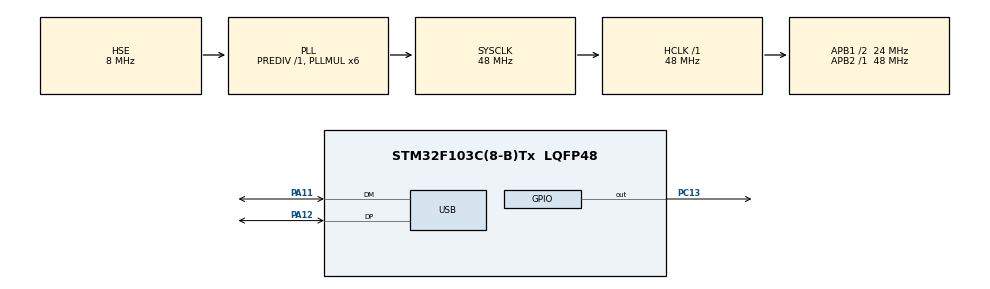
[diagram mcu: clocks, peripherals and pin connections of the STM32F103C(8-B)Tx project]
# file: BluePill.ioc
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Mcu.Family=STM32F1
Mcu.Name=STM32F103C(8-B)Tx
Mcu.Package=LQFP48
NVIC.PriorityGroup=NVIC_PRIORITYGROUP_4
NVIC.TIM1_UP_IRQn=true\:3\:0\:true\:false\:true\:true\:true
NVIC.TIM2_IRQn=true\:4\:0\:true\:false\:true\:true\:true
NVIC.USB_HP_CAN1_TX_IRQn=true\:1\:0\:true\:false\:true\:true\:true
NVIC.USB_LP_CAN1_RX0_IRQn=true\:2\:0\:true\:false\:true\:true\:true
PA11.Mode=Device
PA11.Signal=USB_DM
PA12.Mode=Device
PA12.Signal=USB_DP
PC13-TAMPER-RTC.Signal=GPIO_Output
PD0-OSC_IN.Mode=HSE-External-Oscillator
PD0-OSC_IN.Signal=RCC_OSC_IN
PD1-OSC_OUT.Mode=HSE-External-Oscillator
PD1-OSC_OUT.Signal=RCC_OSC_OUT
ProjectManager.HeapSize=0x200
ProjectManager.StackSize=0x400
ProjectManager.TargetToolchain=STM32CubeIDE
RCC.AHBFreq_Value=48000000
RCC.APB1CLKDivider=RCC_HCLK_DIV2
RCC.APB1Freq_Value=24000000
RCC.APB1TimFreq_Value=48000000
RCC.APB2Freq_Value=48000000
RCC.APB2TimFreq_Value=48000000
RCC.HCLKFreq_Value=48000000
RCC.PLLMUL=RCC_PLL_MUL6
RCC.PLLSourceVirtual=RCC_PLLSOURCE_HSE
RCC.SYSCLKFreq_VALUE=48000000
RCC.SYSCLKSource=RCC_SYSCLKSOURCE_PLLCLK
RCC.USBFreq_Value=48000000
TIM1.AutoReloadPreload=TIM_AUTORELOAD_PRELOAD_ENABLE
TIM1.Period=60000
TIM1.Prescaler=48000
TIM1.RepetitionCounter=4
TIM2.AutoReloadPreload=TIM_AUTORELOAD_PRELOAD_ENABLE
TIM2.Period=1000
TIM2.Prescaler=48000
USB_DEVICE.CLASS_NAME_FS=HID
USB_DEVICE.PID_HID_FS=22352
USB_DEVICE.VID=1155
USB_DEVICE.VirtualMode=Hid
USB_DEVICE.VirtualModeFS=Hid_FS
VP_SYS_VS_ND.Mode=No_Debug
VP_TIM1_VS_ClockSourceINT.Mode=Internal
VP_TIM2_VS_ClockSourceINT.Mode=Internal
VP_USB_DEVICE_VS_USB_DEVICE_HID_FS.Mode=HID_FS
board=custom

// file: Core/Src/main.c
/* USER CODE BEGIN Header */
/**
  ******************************************************************************
  * @file           : main.c
  * @brief          : Main program body
  ******************************************************************************
  * @attention
  *
  * <h2><center>&copy; Copyright (c) 2020 STMicroelectronics.
  * All rights reserved.</center></h2>
  *
  * This software component is licensed by ST under BSD 3-Clause license,
  * the "License"; You may not use this file except in compliance with the
  * License. You may obtain a copy of the License at:
  *                        opensource.org/licenses/BSD-3-Clause
  *
  ******************************************************************************
  */
/* USER CODE END Header */

#include "main.h"
#include "usb_device.h"

/* USER CODE BEGIN Includes */
#include "usbd_hid.h"
/* USER CODE END Includes */

/* USER CODE BEGIN PD */
#define MBUFSIZ 5
/* USER CODE END PD */

TIM_HandleTypeDef htim1;
TIM_HandleTypeDef htim2;

/* USER CODE BEGIN PV */
static __IO uint8_t TIM1Cplt;
static __IO uint8_t TIM2Cplt;
static int8_t mbuf[MBUFSIZ];
/* USER CODE END PV */

void SystemClock_Config(void);
static void MX_GPIO_Init(void);
static void MX_TIM1_Init(void);
static void MX_TIM2_Init(void);
/* USER CODE BEGIN PFP */
static void Mouse_SendData(void);
/* USER CODE END PFP */

/* USER CODE BEGIN 0 */
extern USBD_HandleTypeDef hUsbDeviceFS;
/* USER CODE END 0 */

int main(void)
{

  /* MCU Configuration--------------------------------------------------------*/

  /* Reset of all peripherals, Initializes the Flash interface and the Systick. */
  HAL_Init();

  /* Configure the system clock */
  SystemClock_Config();

  /* Initialize all configured peripherals */
  MX_GPIO_Init();
  MX_TIM1_Init();
  MX_TIM2_Init();
  MX_USB_DEVICE_Init();
  /* USER CODE BEGIN 2 */
  // Update ARR for TIM1
  htim1.Instance->EGR |= TIM_EGR_UG;
  __HAL_TIM_CLEAR_IT(&htim1, TIM_IT_UPDATE);
  // Update ARR for TIM2
  htim2.Instance->EGR |= TIM_EGR_UG;
  __HAL_TIM_CLEAR_IT(&htim2, TIM_IT_UPDATE);
  // Start TIM1
  TIM1Cplt = 0;
  HAL_TIM_Base_Start_IT(&htim1);
  /* USER CODE END 2 */

  /* Infinite loop */
  while (1)
  {

    /* USER CODE BEGIN 3 */
	  Mouse_SendData();
  }
  /* USER CODE END 3 */
}

void SystemClock_Config(void)
{
  RCC_OscInitTypeDef RCC_OscInitStruct = {0};
  RCC_ClkInitTypeDef RCC_ClkInitStruct = {0};
  RCC_PeriphCLKInitTypeDef PeriphClkInit = {0};

  /** Initializes the CPU, AHB and APB busses clocks
  */
  RCC_OscInitStruct.OscillatorType = RCC_OSCILLATORTYPE_HSE;
  RCC_OscInitStruct.HSEState = RCC_HSE_ON;
  RCC_OscInitStruct.HSEPredivValue = RCC_HSE_PREDIV_DIV1;
  RCC_OscInitStruct.HSIState = RCC_HSI_ON;
  RCC_OscInitStruct.PLL.PLLState = RCC_PLL_ON;
  RCC_OscInitStruct.PLL.PLLSource = RCC_PLLSOURCE_HSE;
  RCC_OscInitStruct.PLL.PLLMUL = RCC_PLL_MUL6;
  if (HAL_RCC_OscConfig(&RCC_OscInitStruct) != HAL_OK)
  {
    Error_Handler();
  }
  /** Initializes the CPU, AHB and APB busses clocks
  */
  RCC_ClkInitStruct.ClockType = RCC_CLOCKTYPE_HCLK|RCC_CLOCKTYPE_SYSCLK
                              |RCC_CLOCKTYPE_PCLK1|RCC_CLOCKTYPE_PCLK2;
  RCC_ClkInitStruct.SYSCLKSource = RCC_SYSCLKSOURCE_PLLCLK;
  RCC_ClkInitStruct.AHBCLKDivider = RCC_SYSCLK_DIV1;
  RCC_ClkInitStruct.APB1CLKDivider = RCC_HCLK_DIV2;
  RCC_ClkInitStruct.APB2CLKDivider = RCC_HCLK_DIV1;

  if (HAL_RCC_ClockConfig(&RCC_ClkInitStruct, FLASH_LATENCY_1) != HAL_OK)
  {
    Error_Handler();
  }
  PeriphClkInit.PeriphClockSelection = RCC_PERIPHCLK_USB;
  PeriphClkInit.UsbClockSelection = RCC_USBCLKSOURCE_PLL;
  if (HAL_RCCEx_PeriphCLKConfig(&PeriphClkInit) != HAL_OK)
  {
    Error_Handler();
  }
}

static void MX_TIM1_Init(void)
{

  TIM_ClockConfigTypeDef sClockSourceConfig = {0};
  TIM_MasterConfigTypeDef sMasterConfig = {0};

  htim1.Instance = TIM1;
  htim1.Init.Prescaler = 48000;
  htim1.Init.CounterMode = TIM_COUNTERMODE_UP;
  htim1.Init.Period = 60000;
  //htim1.Init.Period = 2000;
  htim1.Init.ClockDivision = TIM_CLOCKDIVISION_DIV1;
  htim1.Init.RepetitionCounter = 4;
  htim1.Init.AutoReloadPreload = TIM_AUTORELOAD_PRELOAD_ENABLE;
  if (HAL_TIM_Base_Init(&htim1) != HAL_OK)
  {
    Error_Handler();
  }
  sClockSourceConfig.ClockSource = TIM_CLOCKSOURCE_INTERNAL;
  if (HAL_TIM_ConfigClockSource(&htim1, &sClockSourceConfig) != HAL_OK)
  {
    Error_Handler();
  }
  sMasterConfig.MasterOutputTrigger = TIM_TRGO_RESET;
  sMasterConfig.MasterSlaveMode = TIM_MASTERSLAVEMODE_DISABLE;
  if (HAL_TIMEx_MasterConfigSynchronization(&htim1, &sMasterConfig) != HAL_OK)
  {
    Error_Handler();
  }

}

static void MX_TIM2_Init(void)
{

  TIM_ClockConfigTypeDef sClockSourceConfig = {0};
  TIM_MasterConfigTypeDef sMasterConfig = {0};

  htim2.Instance = TIM2;
  htim2.Init.Prescaler = 48000;
  htim2.Init.CounterMode = TIM_COUNTERMODE_UP;
  htim2.Init.Period = 1000;
  htim2.Init.ClockDivision = TIM_CLOCKDIVISION_DIV1;
  htim2.Init.AutoReloadPreload = TIM_AUTORELOAD_PRELOAD_ENABLE;
  if (HAL_TIM_Base_Init(&htim2) != HAL_OK)
  {
    Error_Handler();
  }
  sClockSourceConfig.ClockSource = TIM_CLOCKSOURCE_INTERNAL;
  if (HAL_TIM_ConfigClockSource(&htim2, &sClockSourceConfig) != HAL_OK)
  {
    Error_Handler();
  }
  sMasterConfig.MasterOutputTrigger = TIM_TRGO_RESET;
  sMasterConfig.MasterSlaveMode = TIM_MASTERSLAVEMODE_DISABLE;
  if (HAL_TIMEx_MasterConfigSynchronization(&htim2, &sMasterConfig) != HAL_OK)
  {
    Error_Handler();
  }

}

static void MX_GPIO_Init(void)
{
  GPIO_InitTypeDef GPIO_InitStruct = {0};

  /* GPIO Ports Clock Enable */
  __HAL_RCC_GPIOC_CLK_ENABLE();
  __HAL_RCC_GPIOD_CLK_ENABLE();
  __HAL_RCC_GPIOA_CLK_ENABLE();

  /*Configure GPIO pin Output Level */
  HAL_GPIO_WritePin(GPIOC, GPIO_PIN_13, GPIO_PIN_RESET);

  /*Configure GPIO pin : PC13 */
  GPIO_InitStruct.Pin = GPIO_PIN_13;
  GPIO_InitStruct.Mode = GPIO_MODE_OUTPUT_PP;
  GPIO_InitStruct.Pull = GPIO_NOPULL;
  GPIO_InitStruct.Speed = GPIO_SPEED_FREQ_LOW;
  HAL_GPIO_Init(GPIOC, &GPIO_InitStruct);

}

/* USER CODE BEGIN 4 */
static void Mouse_SendData(void)
{
	if (TIM1Cplt == 1) {
		mbuf[0] = mbuf[2] = mbuf[3] = mbuf[4] = 0;
		mbuf[1] = 100;
		USBD_HID_SendReport(&hUsbDeviceFS, (uint8_t*)mbuf, MBUFSIZ);
		TIM1Cplt = 0;
		HAL_GPIO_TogglePin(GPIOC, GPIO_PIN_13);
	}
	if (TIM2Cplt == 1) {
		mbuf[0] = mbuf[2] = mbuf[3] = mbuf[4] = 0;
		mbuf[1] = -100;
		USBD_HID_SendReport(&hUsbDeviceFS, (uint8_t*)mbuf, MBUFSIZ);
		TIM2Cplt = 0;
		HAL_GPIO_TogglePin(GPIOC, GPIO_PIN_13);
	}
}

void HAL_TIM_PeriodElapsedCallback(TIM_HandleTypeDef *htim)
{
	if (htim == &htim1) {
		TIM1Cplt = 1;
		HAL_TIM_Base_Start_IT(&htim2);
	}
	if (htim == &htim2) {
		TIM2Cplt = 1;
		HAL_TIM_Base_Stop_IT(&htim2);
	}
}

/* USER CODE END 4 */

void Error_Handler(void)
{
}

/************************ (C) COPYRIGHT STMicroelectronics *****END OF FILE****/
